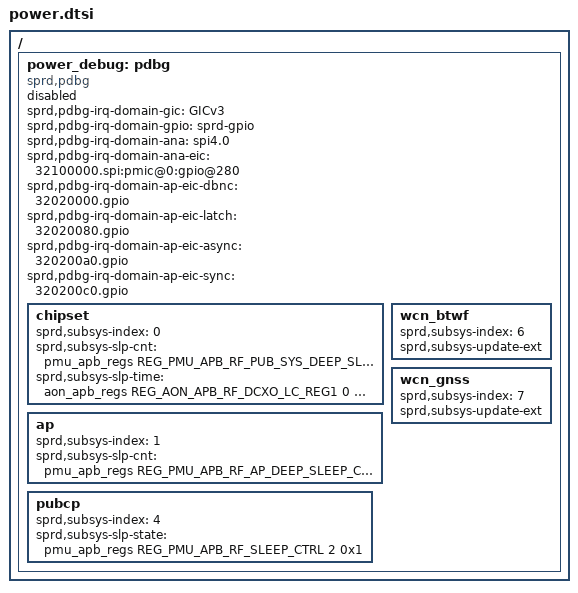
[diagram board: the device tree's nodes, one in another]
// SPDX-License-Identifier: (GPL-2.0+ OR MIT)
/*
 * Unisoc power dts file
 *
 * Copyright (C) 2023, Unisoc Inc.
 *
 */
/ {
	power_debug: pdbg {
		compatible                        = "sprd,pdbg";
		status                             = "disabled";
		sprd,pdbg-irq-domain-gic          = "GICv3";
		sprd,pdbg-irq-domain-gpio         = "sprd-gpio";
		sprd,pdbg-irq-domain-ana          = "spi4.0";
		sprd,pdbg-irq-domain-ana-eic      = "32100000.spi:pmic@0:gpio@280";
		sprd,pdbg-irq-domain-ap-eic-dbnc  = "32020000.gpio";
		sprd,pdbg-irq-domain-ap-eic-latch = "32020080.gpio";
		sprd,pdbg-irq-domain-ap-eic-async = "320200a0.gpio";
		sprd,pdbg-irq-domain-ap-eic-sync  = "320200c0.gpio";
		chipset {
			sprd,subsys-index = <0>;
			sprd,subsys-slp-cnt = <&pmu_apb_regs REG_PMU_APB_RF_PUB_SYS_DEEP_SLEEP_CNT 0 0xff>;
			sprd,subsys-slp-time = <&aon_apb_regs REG_AON_APB_RF_DCXO_LC_REG1 0 0xffffffff>;
		};
		ap {
			sprd,subsys-index = <1>;
			sprd,subsys-slp-cnt = <&pmu_apb_regs REG_PMU_APB_RF_AP_DEEP_SLEEP_CNT 0 0xff>;
		};
		pubcp {
			sprd,subsys-index = <4>;
			sprd,subsys-slp-state = <&pmu_apb_regs REG_PMU_APB_RF_SLEEP_CTRL 2 0x1>;
		};
		wcn_btwf {
			sprd,subsys-index = <6>;
			sprd,subsys-update-ext;
		};
		wcn_gnss {
			sprd,subsys-index = <7>;
			sprd,subsys-update-ext;
		};
	};
};
